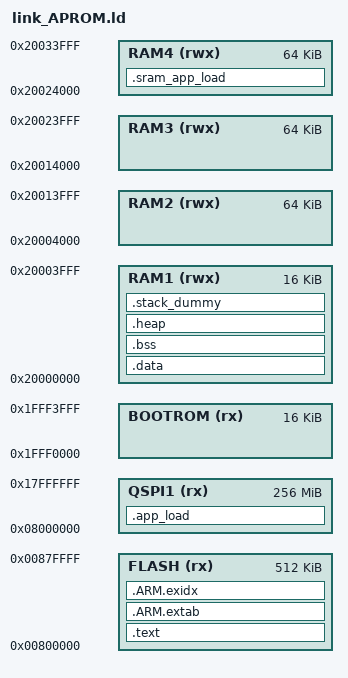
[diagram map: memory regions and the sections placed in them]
/**
 ******************************************************************************
 * @file      LinkerScript.ld
 * @author    Auto-generated by STM32CubeIDE
 * @brief     Linker script for STM32F103C4Tx Device from STM32F1 series
 *                      16Kbytes FLASH
 *                      6Kbytes RAM
 *
 *            Set heap size, stack size and stack location according
 *            to application requirements.
 *
 *            Set memory bank area and size if external memory is used
 ******************************************************************************
 * @attention
 *
 * <h2><center>&copy; Copyright (c) 2020 STMicroelectronics.
 * All rights reserved.</center></h2>
 *
 * This software component is licensed by ST under BSD 3-Clause license,
 * the "License"; You may not use this file except in compliance with the
 * License. You may obtain a copy of the License at:
 *                        opensource.org/licenses/BSD-3-Clause
 *
 ******************************************************************************
 */

/* Memories definition */
MEMORY
{
  BOOTROM (rx)  : ORIGIN = 0x1FFF0000, LENGTH = 16K     /* 16k */
  FLASH (rx)	: ORIGIN = 0x00800000, LENGTH = 512K    /* 512K */
  QSPI1 (rx)	: ORIGIN = 0x08000000, LENGTH = 256M    /* 256M */
  RAM1 (rwx)	: ORIGIN = 0x20000000, LENGTH = 16K     /* 16K */
  RAM2 (rwx)	: ORIGIN = 0x20004000, LENGTH = 64K     /* 64K */
  RAM3 (rwx)	: ORIGIN = 0x20014000, LENGTH = 64K     /* 64K */
  RAM4 (rwx)	: ORIGIN = 0x20024000, LENGTH = 64K     /* 64K */
}

/* Linker script to place sections and symbol values. Should be used together
 * with other linker script that defines memory regions FLASH and RAM.
 * It references following symbols, which must be defined in code:
 *   Reset_Handler : Entry of reset handler
 *
 * It defines following symbols, which code can use without definition:
 *   __exidx_start
 *   __exidx_end
 *   __copy_table_start__
 *   __copy_table_end__
 *   __zero_table_start__
 *   __zero_table_end__
 *   __etext
 *   __data_start__
 *   __preinit_array_start
 *   __preinit_array_end
 *   __init_array_start
 *   __init_array_end
 *   __fini_array_start
 *   __fini_array_end
 *   __data_end__
 *   __bss_start__
 *   __bss_end__
 *   __end__
 *   end
 *   __HeapLimit
 *   __StackLimit
 *   __StackTop
 *   __stack
 */
ENTRY(Reset_Handler)

SECTIONS
{
	.text :
	{
		KEEP(*(.isr_vector))
		/* style 1 */
		*(.text*)

		/* style 2 : set main.c  link section by first function SystemInit
		*(.text)
		. = 0x0400;
		KEEP(*(.text.SystemInit));
		*/

		KEEP(*(.init))
		KEEP(*(.fini))

		/* .ctors */
		*crtbegin.o(.ctors)
		*crtbegin?.o(.ctors)
		*(EXCLUDE_FILE(*crtend?.o *crtend.o) .ctors)
		*(SORT(.ctors.*))
		*(.ctors)

		/* .dtors */
 		*crtbegin.o(.dtors)
 		*crtbegin?.o(.dtors)
 		*(EXCLUDE_FILE(*crtend?.o *crtend.o) .dtors)
 		*(SORT(.dtors.*))
 		*(.dtors)

		*(.rodata*)

		KEEP(*(.eh_frame*))
	} > FLASH

	.ARM.extab :
	{
		*(.ARM.extab* .gnu.linkonce.armextab.*)
	} > FLASH

	__exidx_start = .;
	.ARM.exidx :
	{
		*(.ARM.exidx* .gnu.linkonce.armexidx.*)
	} > FLASH
	__exidx_end = .;

	/* To copy multiple ROM to RAM sections,
	 * uncomment .copy.table section and,
	 * define __STARTUP_COPY_MULTIPLE in startup_ARMCMx.S */
	/*
	.copy.table :
	{
		. = ALIGN(4);
		__copy_table_start__ = .;
		LONG (__etext)
		LONG (__data_start__)
		LONG (__data_end__ - __data_start__)
		LONG (__etext2)
		LONG (__data2_start__)
		LONG (__data2_end__ - __data2_start__)
		__copy_table_end__ = .;
	} > FLASH
	*/

	/* To clear multiple BSS sections,
	 * uncomment .zero.table section and,
	 * define __STARTUP_CLEAR_BSS_MULTIPLE in startup_ARMCMx.S */
	/*
	.zero.table :
	{
		. = ALIGN(4);
		__zero_table_start__ = .;
		LONG (__bss_start__)
		LONG (__bss_end__ - __bss_start__)
		LONG (__bss2_start__)
		LONG (__bss2_end__ - __bss2_start__)
		__zero_table_end__ = .;
	} > FLASH
	*/

	__etext = .;

	.data : AT (__etext)
	{
		__data_start__ = .;
		*(vtable)
		*(.data*)

		. = ALIGN(4);
		/* preinit data */
		PROVIDE_HIDDEN (__preinit_array_start = .);
		KEEP(*(.preinit_array))
		PROVIDE_HIDDEN (__preinit_array_end = .);

		. = ALIGN(4);
		/* init data */
		PROVIDE_HIDDEN (__init_array_start = .);
		KEEP(*(SORT(.init_array.*)))
		KEEP(*(.init_array))
		PROVIDE_HIDDEN (__init_array_end = .);


		. = ALIGN(4);
		/* finit data */
		PROVIDE_HIDDEN (__fini_array_start = .);
		KEEP(*(SORT(.fini_array.*)))
		KEEP(*(.fini_array))
		PROVIDE_HIDDEN (__fini_array_end = .);

		KEEP(*(.jcr*))
		. = ALIGN(4);
		/* All data end */
		__data_end__ = .;

	} > RAM1

	.bss :
	{
		. = ALIGN(4);
		__bss_start__ = .;
		*(.bss*)
		*(COMMON)
		. = ALIGN(4);
		__bss_end__ = .;
	} > RAM1

	.heap (COPY):
	{
		__end__ = .;
		PROVIDE(end = .);
		*(.heap*)
		__HeapLimit = .;
	} > RAM1

	/* .stack_dummy section doesn't contains any symbols. It is only
	 * used for linker to calculate size of stack sections, and assign
	 * values to stack symbols later */

	.stack_dummy (COPY):
	{
		*(.stack*)
	} > RAM1

	/* Set stack top to end of RAM, and stack limit move down by
	 * size of stack_dummy section */
    __StackTop = ORIGIN(RAM1) + LENGTH(RAM1) - 0x100; /*0x20000f00~0x2000ffc*/
	__StackLimit = __StackTop - SIZEOF(.stack_dummy);
	PROVIDE(__stack = __StackTop);

	/* Check if data + heap + stack exceeds RAM limit */
	ASSERT(__StackLimit >= __HeapLimit, "region RAM overflowed with stack")

    .app_load :
    {
        . = ALIGN(4);
        . = ALIGN(4);
    } > QSPI1

    .sram_app_load :
    {
        . = ALIGN(4);
    } > RAM4

}
